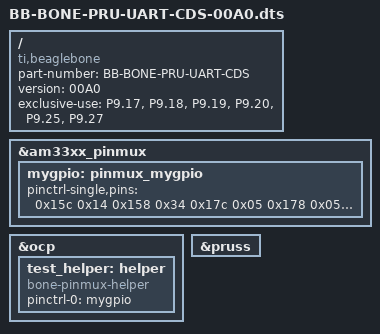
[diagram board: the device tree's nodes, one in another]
/*
* dts file BB-BONE-PRU-UART-CDS-00A0.dts
*/
/dts-v1/;
/plugin/;

/ {
  compatible = "ti,beaglebone", "ti,beaglebone-black";

  /* identification */
  part-number = "BB-BONE-PRU-UART-CDS";
  version = "00A0";

  exclusive-use =
    "P9.17",	/*PRU_UART0_TX*/
    "P9.18",	/*PRU_UART0_RX*/
    "P9.19",	/*PRU_UART0_RTS*/
    "P9.20",	/*PRU_UART0_CTS*/
    "P9.25",	/*PRU_PRU0_r30_7 (UART0_TXE)*/
    "P9.27";	/*PRU_PRU0_r30_5 (UART0_RXE)*/
  
  fragment@0 {
    target = <&am33xx_pinmux>;
    __overlay__ {
      mygpio: pinmux_mygpio{
        pinctrl-single,pins = <
          0x15c 0x14	/*spi0_cs0.pr1_uart0_txd       |slw-fst|O|PU|P-ud EN|MODE4*/
          0x158 0x34	/*spi0_d1.pr1_uart0_rxd        |slw-fst|I|PU|P-ud EN|MODE4*/
          0x17c 0x05	/*uart1_rtsn.pr1_uart0_rts_n   |slw-fst|O|PD|P-ud EN|MODE5*/
          0x178 0x05	/*uart1_ctsn.pr1_uart0_cts_n   |slw-fst|O|PD|P-ud EN|MODE5*/
          0x1ac 0x05	/*spi0_d0.pr1_pru0_pru_r30_7   |slw-fst|O|PD|P-ud EN|MODE5*/
          0x1a4 0x15	/*spi0_sclk.pr1_pru0_pru_r30_5 |slw-fst|O|PU|P-ud EN|MODE5*/
 
          >;
      };
    };
  };

  fragment@1 {
    target = <&ocp>;
    __overlay__ {
      test_helper: helper {
        compatible = "bone-pinmux-helper";
        pinctrl-names = "default";
        pinctrl-0 = <&mygpio>;
        status = "okay";
      };
    };
  };

  fragment@2{
  target = <&pruss>;
    __overlay__ {
      status = "okay";
    };
  };
};
